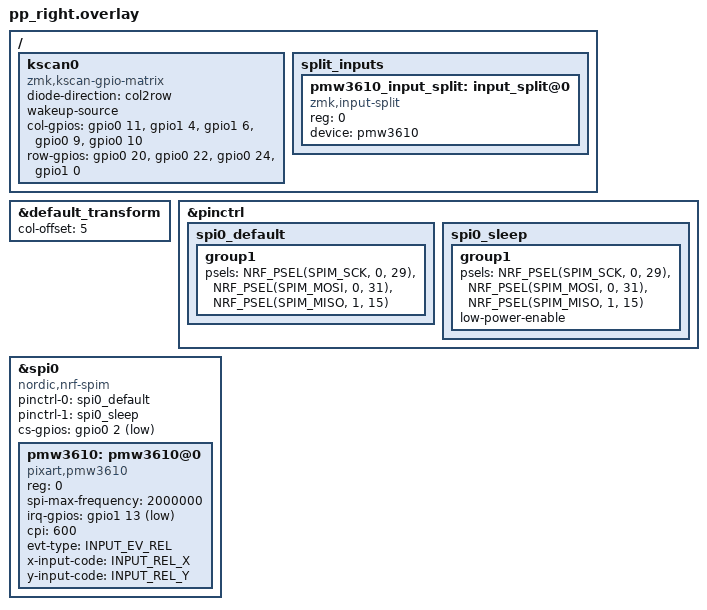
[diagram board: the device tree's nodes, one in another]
#include "pp_left-layout.dtsi"

/ {
    kscan0: kscan0 {
        compatible = "zmk,kscan-gpio-matrix";
        diode-direction = "col2row";
        wakeup-source;

        col-gpios
            = <&gpio0 11 GPIO_ACTIVE_HIGH>
            , <&gpio1 4 GPIO_ACTIVE_HIGH>
            , <&gpio1 6 GPIO_ACTIVE_HIGH>
            , <&gpio0 9 GPIO_ACTIVE_HIGH>
            , <&gpio0 10 GPIO_ACTIVE_HIGH>
            ;

        row-gpios
            = <&gpio0 20 (GPIO_ACTIVE_HIGH | GPIO_PULL_DOWN)>
            , <&gpio0 22 (GPIO_ACTIVE_HIGH | GPIO_PULL_DOWN)>
            , <&gpio0 24 (GPIO_ACTIVE_HIGH | GPIO_PULL_DOWN)>
            , <&gpio1 0 (GPIO_ACTIVE_HIGH | GPIO_PULL_DOWN)>
            ;
    };
};

&default_transform {
    col-offset = <5>;
};

#include <zephyr/dt-bindings/input/input-event-codes.h>
#include <zephyr/dt-bindings/pinctrl/nrf-pinctrl.h>

&pinctrl {
    spi0_default: spi0_default {
        group1 {
                psels = <NRF_PSEL(SPIM_SCK, 0, 29)>,
                    <NRF_PSEL(SPIM_MOSI, 0, 31)>,
                    <NRF_PSEL(SPIM_MISO, 1, 15)>;
        };
    };

    spi0_sleep: spi0_sleep {
        group1 {
                psels = <NRF_PSEL(SPIM_SCK, 0, 29)>,
                    <NRF_PSEL(SPIM_MOSI, 0, 31)>,
                    <NRF_PSEL(SPIM_MISO, 1, 15)>;
            low-power-enable;
        };
    };
};

&spi0 {
    status = "okay";
    compatible = "nordic,nrf-spim";
    pinctrl-0 = <&spi0_default>;
    pinctrl-1 = <&spi0_sleep>;
    pinctrl-names = "default", "sleep";
    cs-gpios = <&gpio0 2 GPIO_ACTIVE_LOW>;

    pmw3610: pmw3610@0 {
        compatible = "pixart,pmw3610";
        reg = <0>;
        status = "okay";
        spi-max-frequency = <2000000>;
        irq-gpios = <&gpio1 13 (GPIO_ACTIVE_LOW | GPIO_PULL_UP)>;
        cpi = <600>;
        evt-type = <INPUT_EV_REL>;
        x-input-code = <INPUT_REL_X>;
        y-input-code = <INPUT_REL_Y>;
    };
};

/ {
    split_inputs {
        #address-cells = <1>;
        #size-cells = <0>;

        pmw3610_input_split: input_split@0 {
            compatible = "zmk,input-split";
            reg = <0>;
            device = <&pmw3610>;
        };
    };
};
